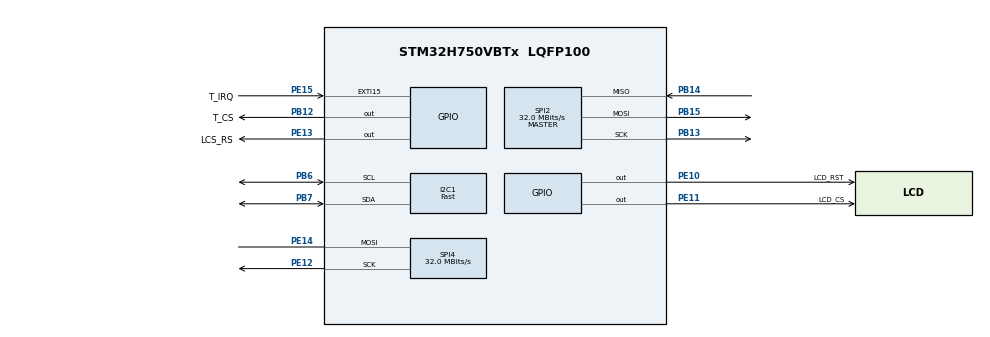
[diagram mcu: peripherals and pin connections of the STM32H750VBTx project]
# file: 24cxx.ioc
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CORTEX_M7.CPU_DCache=Enabled
CORTEX_M7.CPU_ICache=Enabled
I2C1.CustomTiming=Disabled
I2C1.I2C_Speed_Mode=I2C_Fast
I2C1.Timing=0x00602173
Mcu.Family=STM32H7
Mcu.Name=STM32H750VBTx
Mcu.Package=LQFP100
NVIC.EXTI15_10_IRQn=true\:0\:0\:false\:false\:true\:true\:true\:true
NVIC.PriorityGroup=NVIC_PRIORITYGROUP_4
NVIC.SPI2_IRQn=true\:0\:0\:false\:false\:true\:true\:true\:true
NVIC.SPI4_IRQn=true\:0\:0\:false\:false\:true\:true\:true\:true
PB12.GPIO_Label=T_CS
PB12.GPIO_PuPd=GPIO_PULLUP
PB12.GPIO_Speed=GPIO_SPEED_FREQ_VERY_HIGH
PB12.PinState=GPIO_PIN_SET
PB12.Signal=GPIO_Output
PB13.Mode=Full_Duplex_Master
PB13.Signal=SPI2_SCK
PB14.Mode=Full_Duplex_Master
PB14.Signal=SPI2_MISO
PB15.Mode=Full_Duplex_Master
PB15.Signal=SPI2_MOSI
PB6.GPIO_Pu=GPIO_PULLUP
PB6.GPIO_Speed=GPIO_SPEED_FREQ_VERY_HIGH
PB6.Mode=I2C
PB6.Signal=I2C1_SCL
PB7.GPIO_Pu=GPIO_PULLUP
PB7.GPIO_Speed=GPIO_SPEED_FREQ_VERY_HIGH
PB7.Mode=I2C
PB7.Signal=I2C1_SDA
PE10.GPIO_Label=LCD_RST
PE10.GPIO_PuPd=GPIO_PULLUP
PE10.GPIO_Speed=GPIO_SPEED_FREQ_VERY_HIGH
PE10.PinState=GPIO_PIN_SET
PE10.Signal=GPIO_Output
PE11.GPIO_Label=LCD_CS
PE11.GPIO_PuPd=GPIO_PULLUP
PE11.GPIO_Speed=GPIO_SPEED_FREQ_VERY_HIGH
PE11.PinState=GPIO_PIN_SET
PE11.Signal=GPIO_Output
PE12.Mode=Simplex_Bidirectional_Master
PE12.Signal=SPI4_SCK
PE13.GPIO_Label=LCS_RS
PE13.GPIO_PuPd=GPIO_PULLUP
PE13.GPIO_Speed=GPIO_SPEED_FREQ_VERY_HIGH
PE13.PinState=GPIO_PIN_SET
PE13.Signal=GPIO_Output
PE14.Mode=Simplex_Bidirectional_Master
PE14.Signal=SPI4_MOSI
PE15.GPIO_Label=T_IRQ
PE15.GPIO_ModeDefaultEXTI=GPIO_MODE_IT_FALLING
PE15.GPIO_PuPd=GPIO_PULLUP
PE15.Signal=GPXTI15
PH0-OSC_IN\ (PH0).Mode=HSE-External-Oscillator
PH0-OSC_IN\ (PH0).Signal=RCC_OSC_IN
PH1-OSC_OUT\ (PH1).Mode=HSE-External-Oscillator
PH1-OSC_OUT\ (PH1).Signal=RCC_OSC_OUT
ProjectManager.HeapSize=0x200
ProjectManager.StackSize=0x400
ProjectManager.TargetToolchain=STM32CubeIDE
RCC.ADCFreq_Value=50390625
RCC.APB1Freq_Value=120000000
RCC.APB2Freq_Value=120000000
RCC.APB3Freq_Value=120000000
RCC.APB4Freq_Value=120000000
RCC.CortexFreq_Value=240000000
RCC.DIVM1=5
RCC.DIVN1=96
RCC.HCLKFreq_Value=120000000
RCC.HPRE=RCC_HCLK_DIV2
RCC.I2C123CLockSelection=RCC_I2C123CLKSOURCE_HSI
RCC.PLLSourceVirtual=RCC_PLLSOURCE_HSE
RCC.SPI123CLockSelection=RCC_SPI123CLKSOURCE_CLKP
RCC.SYSCLKFreq_VALUE=240000000
RCC.SYSCLKSource=RCC_SYSCLKSOURCE_PLLCLK
RCC.Spi45ClockSelection=RCC_SPI45CLKSOURCE_HSI
RCC.USBFreq_Value=240000000
SPI2.CalculateBaudRate=32.0 MBits/s
SPI2.Direction=SPI_DIRECTION_2LINES
SPI2.Mode=SPI_MODE_MASTER
SPI2.VirtualType=VM_MASTER
SPI4.CalculateBaudRate=32.0 MBits/s
SPI4.Direction=SPI_DIRECTION_1LINE
SPI4.Mode=SPI_MODE_MASTER
SPI4.VirtualType=VM_MASTER
board=custom

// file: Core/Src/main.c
/* USER CODE BEGIN Header */
/**
  ******************************************************************************
  * @file           : main.c
  * @brief          : Main program body
  ******************************************************************************
  * @attention
  *
  * Copyright (c) 2023 STMicroelectronics.
  * All rights reserved.
  *
  * This software is licensed under terms that can be found in the LICENSE file
  * in the root directory of this software component.
  * If no LICENSE file comes with this software, it is provided AS-IS.
  *
  ******************************************************************************
  */
/* USER CODE END Header */
#include "main.h"
#include "i2c.h"
#include "spi.h"
#include "gpio.h"

/* USER CODE BEGIN Includes */
extern I2C_HandleTypeDef hi2c1;

/* USER CODE END Includes */

void SystemClock_Config(void);
void PeriphCommonClock_Config(void);

int main(void)
{

  /* Enable I-Cache---------------------------------------------------------*/
  SCB_EnableICache();

  /* Enable D-Cache---------------------------------------------------------*/
  SCB_EnableDCache();

  /* MCU Configuration--------------------------------------------------------*/

  /* Reset of all peripherals, Initializes the Flash interface and the Systick. */
  HAL_Init();

  /* Configure the system clock */
  SystemClock_Config();

/* Configure the peripherals common clocks */
  PeriphCommonClock_Config();

  /* Initialize all configured peripherals */
  MX_GPIO_Init();
  MX_I2C1_Init();
  MX_SPI2_Init();
  MX_SPI4_Init();

  /* Infinite loop */
  while (1)
  {

  }
}

void SystemClock_Config(void)
{
  RCC_OscInitTypeDef RCC_OscInitStruct = {0};
  RCC_ClkInitTypeDef RCC_ClkInitStruct = {0};

  /** Supply configuration update enable
  */
  HAL_PWREx_ConfigSupply(PWR_LDO_SUPPLY);

  /** Configure the main internal regulator output voltage
  */
  __HAL_PWR_VOLTAGESCALING_CONFIG(PWR_REGULATOR_VOLTAGE_SCALE2);

  while(!__HAL_PWR_GET_FLAG(PWR_FLAG_VOSRDY)) {}

  /** Initializes the RCC Oscillators according to the specified parameters
  * in the RCC_OscInitTypeDef structure.
  */
  RCC_OscInitStruct.OscillatorType = RCC_OSCILLATORTYPE_HSI|RCC_OSCILLATORTYPE_HSE;
  RCC_OscInitStruct.HSEState = RCC_HSE_ON;
  RCC_OscInitStruct.HSIState = RCC_HSI_DIV1;
  RCC_OscInitStruct.HSICalibrationValue = RCC_HSICALIBRATION_DEFAULT;
  RCC_OscInitStruct.PLL.PLLState = RCC_PLL_ON;
  RCC_OscInitStruct.PLL.PLLSource = RCC_PLLSOURCE_HSE;
  RCC_OscInitStruct.PLL.PLLM = 5;
  RCC_OscInitStruct.PLL.PLLN = 96;
  RCC_OscInitStruct.PLL.PLLP = 2;
  RCC_OscInitStruct.PLL.PLLQ = 2;
  RCC_OscInitStruct.PLL.PLLR = 2;
  RCC_OscInitStruct.PLL.PLLRGE = RCC_PLL1VCIRANGE_2;
  RCC_OscInitStruct.PLL.PLLVCOSEL = RCC_PLL1VCOWIDE;
  RCC_OscInitStruct.PLL.PLLFRACN = 0;
  if (HAL_RCC_OscConfig(&RCC_OscInitStruct) != HAL_OK)
  {
    Error_Handler();
  }

  /** Initializes the CPU, AHB and APB buses clocks
  */
  RCC_ClkInitStruct.ClockType = RCC_CLOCKTYPE_HCLK|RCC_CLOCKTYPE_SYSCLK
                              |RCC_CLOCKTYPE_PCLK1|RCC_CLOCKTYPE_PCLK2
                              |RCC_CLOCKTYPE_D3PCLK1|RCC_CLOCKTYPE_D1PCLK1;
  RCC_ClkInitStruct.SYSCLKSource = RCC_SYSCLKSOURCE_PLLCLK;
  RCC_ClkInitStruct.SYSCLKDivider = RCC_SYSCLK_DIV1;
  RCC_ClkInitStruct.AHBCLKDivider = RCC_HCLK_DIV2;
  RCC_ClkInitStruct.APB3CLKDivider = RCC_APB3_DIV1;
  RCC_ClkInitStruct.APB1CLKDivider = RCC_APB1_DIV1;
  RCC_ClkInitStruct.APB2CLKDivider = RCC_APB2_DIV1;
  RCC_ClkInitStruct.APB4CLKDivider = RCC_APB4_DIV1;

  if (HAL_RCC_ClockConfig(&RCC_ClkInitStruct, FLASH_LATENCY_2) != HAL_OK)
  {
    Error_Handler();
  }
}

void PeriphCommonClock_Config(void)
{
  RCC_PeriphCLKInitTypeDef PeriphClkInitStruct = {0};

  /** Initializes the peripherals clock
  */
  PeriphClkInitStruct.PeriphClockSelection = RCC_PERIPHCLK_CKPER;
  PeriphClkInitStruct.CkperClockSelection = RCC_CLKPSOURCE_HSI;
  if (HAL_RCCEx_PeriphCLKConfig(&PeriphClkInitStruct) != HAL_OK)
  {
    Error_Handler();
  }
}

void Error_Handler(void)
{
  __disable_irq();
  while (1)
  {
  }
}
